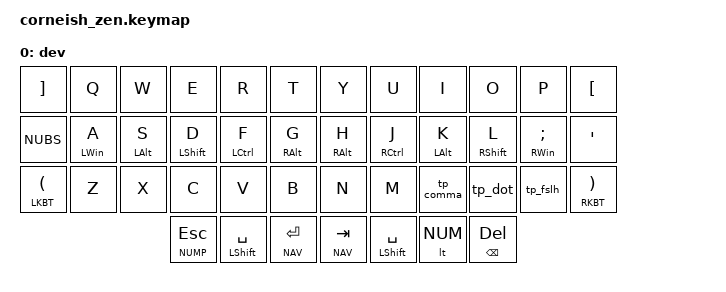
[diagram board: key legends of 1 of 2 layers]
/*
*
* forked_from:
*  https://github.com/ScottCJeffrey/Zen
*
* docs:
*  zmk.dev/docs
*
*/

#include <behaviors.dtsi>
#include <dt-bindings/zmk/keys.h>
#include <dt-bindings/zmk/bt.h>
#include <dt-bindings/zmk/outputs.h>

/* Layers */
#define DEV 0
#define NAV 1
#define NUM 3
#define NUMP 4

&caps_word {
    continue-list = <UNDERSCORE MINUS SPACE>;
};

/ {
    behaviors {
        tldesc: tilde_escape {
            compatible = "zmk,behavior-mod-morph";
            label = "TILDE_ESCAPE";
            #binding-cells = <0>;
            bindings = <&kp ESC>, <&kp TILDE>;
            mods = <(MOD_LSFT|MOD_RSFT)>;
        };

        bspc_del: backspace_delete {
            compatible = "zmk,behavior-mod-morph";
            label = "BACKSPACE_DELETE";
            #binding-cells = <0>;
            bindings = <&kp BACKSPACE>, <&kp DELETE>;
            mods = <(MOD_LSFT|MOD_RSFT)>;
            keep-mods = <(MOD_RSFT)>;
        };
        td_comma: tap_dance_comma {
            compatible = "zmk,behavior-tap-dance";
            label = "TAP_DANCE_COMMA";
            #binding-cells = <0>;
            tapping-term-ms = <200>;
            bindings = <&kp COMMA>, <&kp RA(&kp EQUAL)>;
};
        td_dot: tap_dance_dot {
            compatible = "zmk,behavior-tap-dance";
            label = "TAP_DANCE_DOT";
            #binding-cells = <0>;
            tapping-term-ms = <200>;
            bindings = <&kp DOT>, <&kp RS(&kp 7)>;
};
        td_fslh: tap_dance_fslh {
            compatible = "zmk,behavior-tap-dance";
            label = "TAP_DANCE_FSLH";
            #binding-cells = <0>;
            tapping-term-ms = <200>;
            bindings = <&kp FSLH>, <&kp RS(&kp EQUAL)>;
};
        td_pgup: tap_dance_pgup {
            compatible = "zmk,behavior-tap-dance";
            label = "TAP_DANCE_PGUP";
            #binding-cells = <0>;
            tapping-term-ms = <200>;
            bindings = <&kp PGUP>, <&kp LC(&kp PGUP)>;
};
        td_pgup: tap_dance_pgdn {
            compatible = "zmk,behavior-tap-dance";
            label = "TAP_DANCE_PGDN";
            #binding-cells = <0>;
            tapping-term-ms = <200>;
            bindings = <&kp PGDN>, <&kp LC(&kp PGDN)>;
};
hr: left_hand_positional_hold_tap {
            compatible = "zmk,behavior-hold-tap";
            label = "LEFT_POSITIONAL_HOLD_TAP";
            #binding-cells = <2>;
            flavor = "tap-unless-interrupted";
            tapping-term-ms = <100>;                        // <---[[produces tap if held longer than tapping-term-ms]]
            quick-tap-ms = <200>;
            bindings = <&kp>, <&kp>;
            hold-trigger-key-positions = <5 6 7 8 9 10>;    // <---[[right-hand keys]]
        };
};

/ {
  keymap {
    compatible = "zmk,keymap";
    base_layer {
      label = "dev";
      bindings = <
        // ╭──────────────────┬──────────┬──────────┬─────────────┬────────────┬─────────────╮   ╭─────────────┬─────────────┬──────────────┬───────────┬────────────┬──────────────────╮
              &kp RBKT                       &kp Q              &kp W              &kp E                   &kp R                  &kp T                       &kp Y                   &kp U                    &kp I                     &kp O                &kp P                 &kp LBKT
        // ├──────────────────┼──────────┼──────────┼─────────────┼────────────┼─────────────┤   ├─────────────┼─────────────┼──────────────┼───────────┼────────────┼──────────────────┤
              &kp NUBS                       &ht_tp LWIN A         &ht_tp LALT S         &ht_tp LSHFT D             &ht_tp LCTRL F            &ht_tp RALT G                  &ht_tp RALT H              &ht_tp RCTRL  J             &ht_tp LALT K                &ht_tp RSHFT L          &ht_tp RWIN SEMI         &kp SQT
        // ├──────────────────┼──────────┼──────────┼─────────────┼────────────┼─────────────┤   ├─────────────┼─────────────┼──────────────┼───────────┼────────────┼──────────────────┤
              &mt LKBT LPAR                  &kp Z              &kp X              &kp C                   &kp V                  &kp B                       &kp N                   &kp M                    &tp_comma                 &tp_dot              &tp_fslh              &mt RKBT RPAR
        // ╰──────────────────┴──────────┴──────────┴─────────────┼────────────┼─────────────┤   ├─────────────┼─────────────┼──────────────┴───────────┴────────────┴──────────────────╯
                                                                                &ltu NUMP ESCAPE           &ht_tp LSHFT SPACE           &lt NAV RET                 &lt NAV TAB           &ht_tp LSHFT SPACE         &lt NUM &mt BKSP DEL
        /                                                                        ╰─────────────┴────────────┴─────────────╯     ╰─────────────┴─────────────┴──────────────╯
      >;
    };
    nav_layer {
      label = "nav;
      bindings = <
        // ╭──────────────────┬──────────┬──────────┬─────────────┬────────────┬─────────────╮   ╭─────────────┬─────────────┬──────────────┬───────────┬────────────┬──────────────────╮
              &kp RBKT                      &bt BT_CLR             &bt BT_NXT            &bt BT_PRV                  &out OUT_TOG               &kp CAPS                    &lt CAPS              &tpPG_UP               &kp HOME               &kp SYSREQ         &kp SLCK             &kp PAUSE_BREAK
        // ├──────────────────┼──────────┼──────────┼─────────────┼────────────┼─────────────┤   ├─────────────┼─────────────┼──────────────┼───────────┼────────────┼──────────────────┤
              &kp NUBS                      &ht_tp LWIN A        &ht_tp LALT S       &ht_tp LSHIFT D           &ht_tp LCTRL F         &ht_tp RALT G                  &kp K_APP             &kp LEFT               &kp DOWN               &kp UP             &kp RIGHT            &kp SQT
        // ├──────────────────┼──────────┼──────────┼─────────────┼────────────┼─────────────┤   ├─────────────┼─────────────┼──────────────┼───────────┼────────────┼──────────────────┤
              &mt LKBT LPAR                &kp Z              &kp X            &kp C                  &kp V               &kp B                       &kp INSERT            &tpPG_DOWN             &kp END                &kp_DOT            &kp_FSLH             &mt RKBT RPAR
        // ╰──────────────────┴──────────┴──────────┴─────────────┼────────────┼─────────────┤   ├─────────────┼─────────────┼──────────────┴───────────┴────────────┴──────────────────╯
                                                                                &kp_ESCAPE            &kp_SPACE            &kp_RET                   &kp_TAB                &kp_SPACE              &mt kp_BKSP DEL
        //                                                                   ╰─────────────┴────────────┴─────────────╯   ╰─────────────┴─────────────┴──────────────╯
      >;
    };
  num_layer {
    compatible = "zmk,keymap";
    base_layer {
      label = "num";
      bindings = <
        // ╭──────────────────┬──────────┬──────────┬─────────────┬────────────┬─────────────╮   ╭─────────────┬─────────────┬──────────────┬───────────┬────────────┬──────────────────╮
              &kp GRAVE                     &kp N1            &kp N2           &kp N3                 &kp N4              &kp N5                     &tp NUML N6            &kp N7                 &kp N8                  &kp N9             &kp N0               &kp MINUS
        // ├──────────────────┼──────────┼──────────┼─────────────┼────────────┼─────────────┤   ├─────────────┼─────────────┼──────────────┼───────────┼────────────┼──────────────────┤
              &kp NUBS                      &ht_tp LWIN A        &ht_tp LALT S       &ht_tp LSHIFT D           &ht_tp LCTRL F         &ht_tp RALT G                 &KP_MINUS              &kp N4                 &kp N5                  &kp N6             &kp KP_DIVIDE        &kp PlUS
        // ├──────────────────┼──────────┼──────────┼─────────────┼────────────┼─────────────┤   ├─────────────┼─────────────┼──────────────┼───────────┼────────────┼──────────────────┤
              &mt LSHFT LPAR                &kp Z             &kp X            &kp C                  &kp V               &kp_B                      &KP_PLUS               &kp N1                 &kp N2                  &kp N3             &kp KP_MULTIPLY      &kp EQUAL
        // ╰──────────────────┴──────────┴──────────┴─────────────┼────────────┼─────────────┤   ├─────────────┼─────────────┼──────────────┴───────────┴────────────┴──────────────────╯
                                                                                &kp LCTRL            &kp LGUI             &kp RET                    &KP_N0                 &kp_sep               &kp_RETURN
        //                                                                   ╰─────────────┴────────────┴─────────────╯   ╰─────────────┴─────────────┴──────────────╯
      >;
    };
  nump_layer {
    compatible = "zmk,keymap";
    base_layer {
      label = "nump";
      bindings = <
        // ╭──────────────────┬──────────┬──────────┬─────────────┬────────────┬─────────────╮   ╭─────────────┬─────────────┬──────────────┬───────────┬────────────┬──────────────────╮
              &kp GRAVE                     &kp N1            &kp N2           &kp N3                 &kp N4              &kp N5                     &kp NUML               &kp KP_N7            &kp KP_N8               &kp KP_N9          &kp KP_N0            &kp MIKP_NUS
        // ├──────────────────┼──────────┼──────────┼─────────────┼────────────┼─────────────┤   ├─────────────┼─────────────┼──────────────┼───────────┼────────────┼──────────────────┤
              &kp KP_NUBS                   &kp_A             &kp_S            &kp_D                  &kp_F               &kp_G                      &KP_MIKP_NUS           &kp KP_N4             &ht_tp LCTRL KP_N5         &kp KP_N6          &kp KP_DIVIDE        &kp PlUS
        // ├──────────────────┼──────────┼──────────┼─────────────┼────────────┼─────────────┤   ├─────────────┼─────────────┼──────────────┼───────────┼────────────┼──────────────────┤
              &mt LSHFT LPAR                &kp Z             &kp X            &kp C                  &kp V               &kp_B                      &KP_PLUS               &kp KP_N1             &kp KP_N2               &kp KP_N3          &kp KP_MULTIPLY      &kp EQUAL
        // ╰──────────────────┴──────────┴──────────┴─────────────┼────────────┼─────────────┤   ├─────────────┼─────────────┼──────────────┴───────────┴────────────┴──────────────────╯
                                                                                &kp LCTRL            &kp LGUI             &kp RET                    &KP_KP_N0                 &kp_sep               &kp_RETURKP_N
        //                                                                   ╰─────────────┴────────────┴─────────────╯   ╰─────────────┴─────────────┴──────────────╯
      >;
    };

    // sym_layer {
    //   label = "SYM";
    //   bindings = <
    //     // ╭──────────┬────────────┬──────────┬─────────────┬─────────────┬─────────────╮   ╭─────────────┬─────────────┬──────────────┬─────────────┬────────────┬─────────────╮
    //           &trans     &kp EXCL     &kp AT     &kp HASH      &kp DLLR      &kp PRCNT         &kp CARET     &kp AMPS      &kp STAR       &kp EQUAL     &kp PLUS     &none
    //     // ├──────────┼────────────┼──────────┼─────────────┼─────────────┼─────────────┤   ├─────────────┼─────────────┼──────────────┼─────────────┼────────────┼─────────────┤
    //           &trans     &none        &none      &kp STAR      &kp CARET     &kp DLLR          &kp LBRC      &kp RBRC      &kp PRCNT      &kp AMPS      &kp HASH     &kp GRAVE
    //     // ├──────────┼────────────┼──────────┼─────────────┼─────────────┼─────────────┤   ├─────────────┼─────────────┼──────────────┼─────────────┼────────────┼─────────────┤
    //           &trans     &none        &none      &none         &kp LBKT      &kp RBKT          &kp LT        &kp GT        &kp PIPE       &none         &kp BSLH     &none
    //     // ╰──────────┴────────────┴──────────┴─────────────┼─────────────┼─────────────┤   ├─────────────┼─────────────┼──────────────┴─────────────┴────────────┴─────────────╯
    //                                                  &kp LCTRL     &kp LGUI      &kp RET           &bspc_del     &kp SPACE     &caps_word
    //     //                                        ╰─────────────┴─────────────┴─────────────╯   ╰─────────────┴─────────────┴──────────────╯
    //   >;
    // };

    // nav_layer {
    //   label = "NAV";
    //   bindings = <
    //     // ╭──────────────┬────────────────┬────────────────┬────────────────┬────────────────┬────────────────╮   ╭─────────────┬────────────┬──────────────┬─────────────┬──────────┬────────────╮
    //           &trans         &kp N1           &kp N2           &kp N3           &kp N4           &kp N5               &kp N6        &kp N7       &kp N8         &kp N9        &kp N0     &kp BSPC
    //     // ├──────────────┼────────────────┼────────────────┼────────────────┼────────────────┼────────────────┤   ├─────────────┼────────────┼──────────────┼─────────────┼──────────┼────────────┤
    //           &bt BT_CLR     &bt BT_SEL 0     &bt BT_SEL 1     &bt BT_SEL 2     &bt BT_SEL 3     &bt BT_SEL 4         &kp LEFT      &kp DOWN     &kp UP         &kp RIGHT     &none      &none
    //     // ├──────────────┼────────────────┼────────────────┼────────────────┼────────────────┼────────────────┤   ├─────────────┼────────────┼──────────────┼─────────────┼──────────┼────────────┤
    //           &trans         &none            &none            &none            &none            &none                &none         &none        &none          &none         &none      &none
    //     // ╰──────────────┴────────────────┴────────────────┴────────────────┼────────────────┼────────────────┤   ├─────────────┼────────────┼──────────────┴─────────────┴──────────┴────────────╯
    //                                                            &kp LCTRL        &kp LGUI         &kp RET              &bspc_del     &kp SPACE    &caps_word
    //     //                                                  ╰────────────────┴────────────────┴────────────────╯   ╰─────────────┴────────────┴──────────────╯
    //   >;
    // };

    // num_layer {
    //   label = "NUM";
    //   bindings = <
    //     // ╭────────┬───────────────────────┬───────────────────────┬───────────────────────┬───────────────────────┬───────────╮   ╭─────────────────┬───────────┬────────────┬───────────┬──────────────┬──────────╮
    //          &trans   &kp KP_N1               &kp KP_N2               &kp KP_N3               &kp KP_N4               &kp KP_N5       &kp KP_N6         &kp KP_N7   &kp KP_N8    &kp KP_N9   &kp KP_N0      &kp BSPC
    //     // ├────────┼───────────────────────┼───────────────────────┼───────────────────────┼───────────────────────┼───────────┤   ├─────────────────┼───────────┼────────────┼───────────┼──────────────┼──────────┤
    //          &trans   &kp LS(LC(LA(LG(A))))   &kp LS(LC(LA(LG(B))))   &kp LS(LC(LA(LG(C))))   &kp LS(LC(LA(LG(D))))   &none           &kp KP_ASTERISK   &kp KP_N4   &kp KP_N5    &kp KP_N6   &kp KP_PLUS    &none
    //     // ├────────┼───────────────────────┼───────────────────────┼───────────────────────┼───────────────────────┼───────────┤   ├─────────────────┼───────────┼────────────┼───────────┼──────────────┼──────────┤
    //          &trans   &kp LS(LC(LA(LG(F))))   &kp LS(LC(LA(LG(G))))   &kp LS(LC(LA(LG(H))))   &kp LS(LC(LA(LG(I))))   &none           &kp KP_N0         &kp KP_N1   &kp KP_N2    &kp KP_N3   &kp KP_ENTER   &none
    //     // ╰────────┴───────────────────────┴───────────────────────┴───────────────────────┼───────────────────────┼───────────┤   ├─────────────────┼───────────┼────────────┴───────────┴──────────────┴──────────╯
    //                                                                   &kp LCTRL               &kp LGUI                &kp RET         &bspc_del         &kp SPACE   &caps_word
    //     //                                                          ╰───────────────────────┴───────────────────────┴───────────╯   ╰─────────────────┴───────────┴────────────╯
    //   >;
    // };
  };
};
